AUTOSAR XML (schema 4-0-3)
package /ComponentTypes
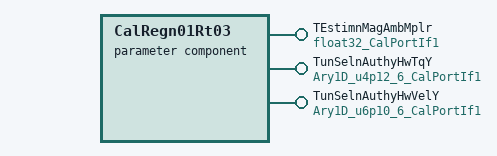
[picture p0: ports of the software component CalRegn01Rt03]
  parameter sw component type CalRegn01Rt03
    provide port TEstimnMagAmbMplr: parameter-provide-com-spec{init-value=0.01, parameter=Val}, provided-interface=float32_CalPortIf1
    provide port TunSelnAuthyHwTqY: parameter-provide-com-spec{init-value=6 x 20480, parameter=Ary1D}, provided-interface=Ary1D_u4p12_6_CalPortIf1
    provide port TunSelnAuthyHwVelY: parameter-provide-com-spec{init-value=6 x 20480, parameter=Ary1D}, provided-interface=Ary1D_u6p10_6_CalPortIf1
